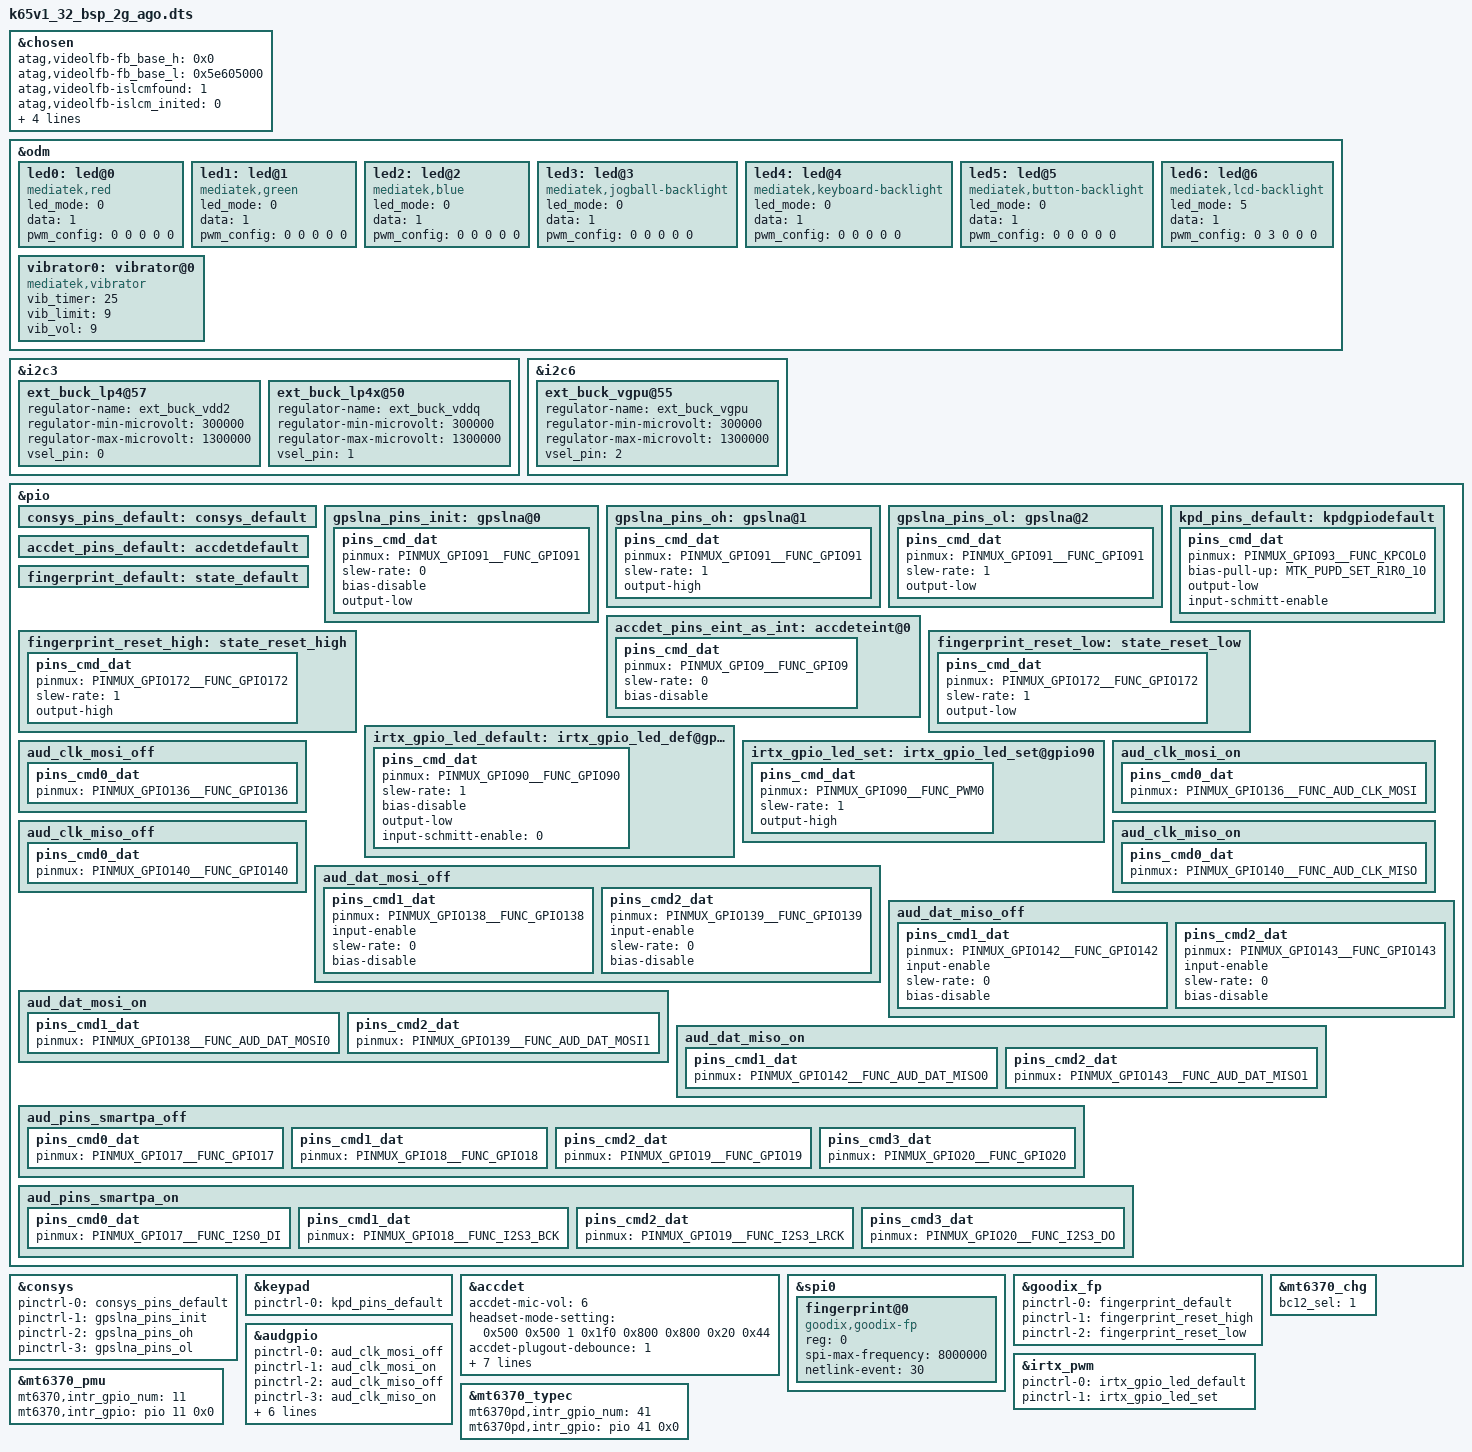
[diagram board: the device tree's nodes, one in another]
// SPDX-License-Identifier: GPL-2.0+
/*
 * Copyright (c) 2019 MediaTek Inc.
 *
 */

#include <dt-bindings/interrupt-controller/arm-gic.h>
#include <dt-bindings/interrupt-controller/irq.h>
#include <dt-bindings/pinctrl/mt6765-pinfunc.h>
#include <dt-bindings/clock/mt6765-clk.h>

/dts-v1/;
/plugin/;

/* chosen */
&chosen {

	/* fpga may has no lk, we need to specify display info here */
	/* fb buffer is reserved using this dts by memory node above */
	atag,videolfb-fb_base_h = <0x0>;
	atag,videolfb-fb_base_l = <0x5e605000>;
	atag,videolfb-islcmfound = <1>;
	/* because no lk, so lcm is not inited */
	atag,videolfb-islcm_inited = <0>;
	atag,videolfb-fps= <6000>;
	atag,videolfb-vramSize= <0x017bb000>;
	atag,videolfb-lcmname= "nt35695B_fhd_dsi_cmd_auo_rt5081_drv";
};

&odm {
	led0:led@0 {
		compatible = "mediatek,red";
		led_mode = <0>;
		data = <1>;
		pwm_config = <0 0 0 0 0>;
	};
	led1:led@1 {
		compatible = "mediatek,green";
		led_mode = <0>;
		data = <1>;
		pwm_config = <0 0 0 0 0>;
	};
	led2:led@2 {
		compatible = "mediatek,blue";
		led_mode = <0>;
		data = <1>;
		pwm_config = <0 0 0 0 0>;
	};
	led3:led@3 {
		compatible = "mediatek,jogball-backlight";
		led_mode = <0>;
		data = <1>;
		pwm_config = <0 0 0 0 0>;
	};
	led4:led@4 {
		compatible = "mediatek,keyboard-backlight";
		led_mode = <0>;
		data = <1>;
		pwm_config = <0 0 0 0 0>;
	};
	led5:led@5 {
		compatible = "mediatek,button-backlight";
		led_mode = <0>;
		data = <1>;
		pwm_config = <0 0 0 0 0>;
	};
	led6:led@6 {
		compatible = "mediatek,lcd-backlight";
		led_mode = <5>;
		data = <1>;
		pwm_config = <0 3 0 0 0>;
	};
	vibrator0:vibrator@0 {
		compatible = "mediatek,vibrator";
		vib_timer = <25>;
		vib_limit = <9>;
		vib_vol= <9>;
	};
};

&i2c3 {
	ext_buck_lp4@57 {
		regulator-name ="ext_buck_vdd2";
		regulator-min-microvolt = <300000>;
		regulator-max-microvolt = <1300000>;
		vsel_pin = <0>;
	};

	ext_buck_lp4x@50 {
		regulator-name ="ext_buck_vddq";
		regulator-min-microvolt = <300000>;
		regulator-max-microvolt = <1300000>;
		vsel_pin = <1>;
	};
};

&i2c6 {
	ext_buck_vgpu@55 {
		regulator-name ="ext_buck_vgpu";
		regulator-min-microvolt = <300000>;
		regulator-max-microvolt = <1300000>;
		vsel_pin = <2>;
	};
};

/* CONSYS GPIO standardization */
&pio {
	consys_pins_default: consys_default {
	};
	gpslna_pins_init: gpslna@0 {
		pins_cmd_dat {
			pinmux = <PINMUX_GPIO91__FUNC_GPIO91>;
			slew-rate = <0>;
			bias-disable;
			output-low;
		};
	};
	gpslna_pins_oh: gpslna@1 {
		pins_cmd_dat {
			pinmux = <PINMUX_GPIO91__FUNC_GPIO91>;
			slew-rate = <1>;
			output-high;
		};
	};
	gpslna_pins_ol: gpslna@2 {
		pins_cmd_dat {
			pinmux = <PINMUX_GPIO91__FUNC_GPIO91>;
			slew-rate = <1>;
			output-low;
		};
	};
};
&consys {
	pinctrl-names = "default", "gps_lna_state_init",
		"gps_lna_state_oh", "gps_lna_state_ol";
	pinctrl-0 = <&consys_pins_default>;
	pinctrl-1 = <&gpslna_pins_init>;
	pinctrl-2 = <&gpslna_pins_oh>;
	pinctrl-3 = <&gpslna_pins_ol>;
	status = "okay";
};
/* CONSYS end */

&keypad {
	pinctrl-names = "default";
	pinctrl-0 = <&kpd_pins_default>;
};

&pio {
	kpd_pins_default: kpdgpiodefault {
		pins_cmd_dat {
			pinmux = <PINMUX_GPIO93__FUNC_KPCOL0>;
			bias-pull-up = <MTK_PUPD_SET_R1R0_10>;
			output-low;
			input-schmitt-enable;
		};
	};
};


/* accdet start */
&accdet {
	accdet-mic-vol = <6>;
	headset-mode-setting = <0x500 0x500 1 0x1f0 0x800 0x800 0x20 0x44>;
	accdet-plugout-debounce = <1>;
	accdet-mic-mode = <1>;
	headset-eint-level-pol = <8>;
	headset-three-key-threshold = <0 80 220 400>;
	headset-three-key-threshold-CDD = <0 121 192 600>;
	headset-four-key-threshold = <0 58 121 192 400>;
	pinctrl-names = "default", "state_eint_as_int";
	pinctrl-0 = <&accdet_pins_default>;
	pinctrl-1 = <&accdet_pins_eint_as_int>;
	status = "okay";
};
&pio {
	accdet_pins_default: accdetdefault {
	};
	accdet_pins_eint_as_int: accdeteint@0 {
		pins_cmd_dat {
			pinmux = <PINMUX_GPIO9__FUNC_GPIO9>;
			slew-rate = <0>;
			bias-disable;
		};
	};
};
/* accdet end */

/* FINGERPRINT start */
&spi0 {
	#address-cells = <1>;
	#size-cells = <0>;
	fingerprint@0 {
		compatible = "goodix,goodix-fp";
		reg = <0>;
		spi-max-frequency = <8000000>;
		netlink-event = <30>;
		status = "okay";
	};
};

&goodix_fp {
	pinctrl-names = "default", "reset_high", "reset_low";
	pinctrl-0 = <&fingerprint_default>;
	pinctrl-1 = <&fingerprint_reset_high>;
	pinctrl-2 = <&fingerprint_reset_low>;
	status = "okay";
};

&pio {
	fingerprint_default: state_default {
	};
	fingerprint_reset_high: state_reset_high {
		pins_cmd_dat {
			pinmux = <PINMUX_GPIO172__FUNC_GPIO172>;
			slew-rate = <1>;
			output-high;
		};
	};
	fingerprint_reset_low: state_reset_low {
		pins_cmd_dat {
			pinmux = <PINMUX_GPIO172__FUNC_GPIO172>;
			slew-rate = <1>;
			output-low;
		};
	};
};
/* FINGERPRINT end */

/* IRTX GPIO end */
&irtx_pwm {
	pinctrl-names = "irtx_gpio_led_default", "irtx_gpio_led_set";
	pinctrl-0 = <&irtx_gpio_led_default>;
	pinctrl-1 = <&irtx_gpio_led_set>;
	status = "okay";
};
&pio {
	irtx_gpio_led_default:irtx_gpio_led_def@gpio90 {
		pins_cmd_dat {
			pinmux = <PINMUX_GPIO90__FUNC_GPIO90>;
			slew-rate = <1>;
			bias-disable;
			output-low;
			input-schmitt-enable = <0>;
		};
	};

	irtx_gpio_led_set:irtx_gpio_led_set@gpio90 {
		pins_cmd_dat {
			pinmux = <PINMUX_GPIO90__FUNC_PWM0>;
			slew-rate = <1>;
			output-high;
		};
	};
};
/* IRTX GPIO Settings -End */

/* AUDIO GPIO standardization */
&audgpio {
	pinctrl-names = "aud_clk_mosi_off",
			"aud_clk_mosi_on",
			"aud_clk_miso_off",
			"aud_clk_miso_on",
			"aud_dat_mosi_off",
			"aud_dat_mosi_on",
			"aud_dat_miso_off",
			"aud_dat_miso_on",
			"aud_smartpa_off",
			"aud_smartpa_on";
	pinctrl-0 = <&aud_clk_mosi_off>;
	pinctrl-1 = <&aud_clk_mosi_on>;
	pinctrl-2 = <&aud_clk_miso_off>;
	pinctrl-3 = <&aud_clk_miso_on>;
	pinctrl-4 = <&aud_dat_mosi_off>;
	pinctrl-5 = <&aud_dat_mosi_on>;
	pinctrl-6 = <&aud_dat_miso_off>;
	pinctrl-7 = <&aud_dat_miso_on>;
	pinctrl-8 = <&aud_pins_smartpa_off>;
	pinctrl-9 = <&aud_pins_smartpa_on>;
	status = "okay";
};

&pio {
	aud_clk_mosi_off: aud_clk_mosi_off {
		pins_cmd0_dat {
			pinmux = <PINMUX_GPIO136__FUNC_GPIO136>;
		};
	};

	aud_clk_mosi_on: aud_clk_mosi_on {
		pins_cmd0_dat {
			pinmux = <PINMUX_GPIO136__FUNC_AUD_CLK_MOSI>;
		};
	};

	aud_clk_miso_off: aud_clk_miso_off {
		pins_cmd0_dat {
			pinmux = <PINMUX_GPIO140__FUNC_GPIO140>;
		};
	};

	aud_clk_miso_on: aud_clk_miso_on {
		pins_cmd0_dat {
			pinmux = <PINMUX_GPIO140__FUNC_AUD_CLK_MISO>;
		};
	};

	aud_dat_mosi_off: aud_dat_mosi_off {
		pins_cmd1_dat {
			pinmux = <PINMUX_GPIO138__FUNC_GPIO138>;
			input-enable;
			slew-rate = <0>;
			bias-disable;
		};
		pins_cmd2_dat {
			pinmux = <PINMUX_GPIO139__FUNC_GPIO139>;
			input-enable;
			slew-rate = <0>;
			bias-disable;
		};
	};

	aud_dat_mosi_on: aud_dat_mosi_on {
		pins_cmd1_dat {
			pinmux = <PINMUX_GPIO138__FUNC_AUD_DAT_MOSI0>;
		};
		pins_cmd2_dat {
			pinmux = <PINMUX_GPIO139__FUNC_AUD_DAT_MOSI1>;
		};
	};

	aud_dat_miso_off: aud_dat_miso_off {
		pins_cmd1_dat {
			pinmux = <PINMUX_GPIO142__FUNC_GPIO142>;
			input-enable;
			slew-rate = <0>;
			bias-disable;
		};
		pins_cmd2_dat {
			pinmux = <PINMUX_GPIO143__FUNC_GPIO143>;
			input-enable;
			slew-rate = <0>;
			bias-disable;
		};
	};

	aud_dat_miso_on: aud_dat_miso_on {
		pins_cmd1_dat {
			pinmux = <PINMUX_GPIO142__FUNC_AUD_DAT_MISO0>;
		};
		pins_cmd2_dat {
			pinmux = <PINMUX_GPIO143__FUNC_AUD_DAT_MISO1>;
		};
	};

	aud_pins_smartpa_off: aud_pins_smartpa_off {
		pins_cmd0_dat {
			pinmux = <PINMUX_GPIO17__FUNC_GPIO17>;
		};
		pins_cmd1_dat {
			pinmux = <PINMUX_GPIO18__FUNC_GPIO18>;
		};
		pins_cmd2_dat {
			pinmux = <PINMUX_GPIO19__FUNC_GPIO19>;
		};
		pins_cmd3_dat {
			pinmux = <PINMUX_GPIO20__FUNC_GPIO20>;
		};
	};

	aud_pins_smartpa_on: aud_pins_smartpa_on {
		pins_cmd0_dat {
			pinmux = <PINMUX_GPIO17__FUNC_I2S0_DI>;
		};
		pins_cmd1_dat {
			pinmux = <PINMUX_GPIO18__FUNC_I2S3_BCK>;
		};
		pins_cmd2_dat {
			pinmux = <PINMUX_GPIO19__FUNC_I2S3_LRCK>;
		};
		pins_cmd3_dat {
			pinmux = <PINMUX_GPIO20__FUNC_I2S3_DO>;
		};
	};
};
/* AUDIO end */

&mt6370_pmu {
	mt6370,intr_gpio_num = <11>; /* direct defined GPIO num */
	mt6370,intr_gpio = <&pio 11 0x0>;
};

&mt6370_typec {
	mt6370pd,intr_gpio_num = <41>; /* direct defined GPIO num */
	mt6370pd,intr_gpio = <&pio 41 0x0>;
};

&mt6370_chg {
	bc12_sel = <1>;
};

#include <k65v1_32_bsp_2g_ago/cust.dtsi>
#include "cust_mt6765_camera.dtsi"
#include "cust_mt6765_touch_1080x1920.dtsi"
/*End of this file, DO NOT ADD ANYTHING HERE*/
